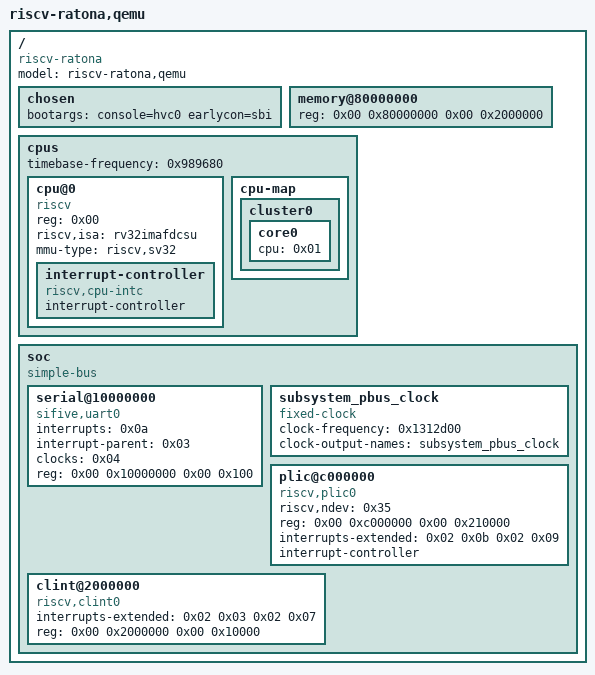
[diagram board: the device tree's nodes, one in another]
/dts-v1/;

/ {
	#address-cells = <0x02>;
	#size-cells = <0x02>;
	compatible = "riscv-ratona";
	model = "riscv-ratona,qemu";

	chosen {
		bootargs = "console=hvc0 earlycon=sbi";
	};

	memory@80000000 {
		device_type = "memory";
		reg = <0x00 0x80000000 0x00 0x2000000>;
	};

	cpus {
		#address-cells = <0x01>;
		#size-cells = <0x00>;
		timebase-frequency = <0x989680>;

		cpu@0 {
			phandle = <0x01>;
			device_type = "cpu";
			reg = <0x00>;
			status = "okay";
			compatible = "riscv";
			riscv,isa = "rv32imafdcsu";
			mmu-type = "riscv,sv32";

			interrupt-controller {
				#interrupt-cells = <0x01>;
				interrupt-controller;
				compatible = "riscv,cpu-intc";
				phandle = <0x02>;
			};
		};

		cpu-map {

			cluster0 {

				core0 {
					cpu = <0x01>;
				};
			};
		};
	};

	soc {
		#address-cells = <0x02>;
		#size-cells = <0x02>;
		compatible = "simple-bus";
		ranges;

		serial@10000000 {
			interrupts = <0x0a>;
			interrupt-parent = <0x03>;
			clocks = <0x04>;
			reg = <0x00 0x10000000 0x00 0x100>;
			compatible = "sifive,uart0";
		};

		subsystem_pbus_clock {
			#clock-cells = <0x00>;
			compatible = "fixed-clock";
			clock-frequency = <0x1312d00>;
			clock-output-names = "subsystem_pbus_clock";
			phandle = <0x04>;
		};

		plic@c000000 {
			phandle = <0x03>;
			riscv,ndev = <0x35>;
			reg = <0x00 0xc000000 0x00 0x210000>;
			interrupts-extended = <0x02 0x0b 0x02 0x09>;
			interrupt-controller;
			compatible = "riscv,plic0";
			#interrupt-cells = <0x01>;
			#address-cells = <0x00>;
		};

		clint@2000000 {
			interrupts-extended = <0x02 0x03 0x02 0x07>;
			reg = <0x00 0x2000000 0x00 0x10000>;
			compatible = "riscv,clint0";
		};
	};
};
